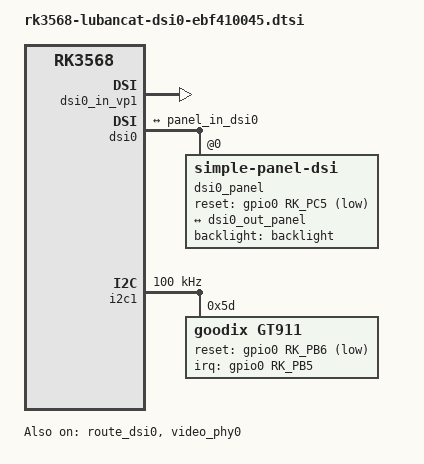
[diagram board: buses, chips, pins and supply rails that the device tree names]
// SPDX-License-Identifier: (GPL-2.0+ OR MIT)
/*
 * Copyright (c) 2020 Rockchip Electronics Co., Ltd.
 *
 */

&route_dsi0 {
	status = "okay";
	connect = <&vp1_out_dsi0>;
};

&video_phy0 {
	status = "okay";
};

&dsi0_in_vp0 {
	status = "disabled";
};

&dsi0_in_vp1 {
	status = "okay";
};

&dsi0 {
	status = "okay";

	dsi0_panel: panel@0 {
		status = "okay";
		compatible = "simple-panel-dsi";
		reg = <0>;
		backlight = <&backlight>;
		reset-gpios = <&gpio0 RK_PC5 GPIO_ACTIVE_LOW>;

		enable-delay-ms = <35>;
		prepare-delay-ms = <6>;
		reset-delay-ms = <0>;
		init-delay-ms = <20>;
		unprepare-delay-ms = <0>;
		disable-delay-ms = <20>;

		size,width = <68>;
		size,height = <121>;

		dsi,flags = <(MIPI_DSI_MODE_VIDEO | MIPI_DSI_MODE_VIDEO_BURST | MIPI_DSI_MODE_LPM | MIPI_DSI_MODE_EOT_PACKET)>;
		dsi,format = <MIPI_DSI_FMT_RGB888>;
		dsi,lanes  = <4>;

		panel-init-sequence = [
			15 00 04 FF 98 81 03
			15 00 02 01 00
			15 00 02 02 00
			15 00 02 03 72
			15 00 02 04 00
			15 00 02 05 00
			15 00 02 06 09
			15 00 02 07 00
			15 00 02 08 00
			15 00 02 09 01
			15 00 02 0A 00
			15 00 02 0B 00
			15 00 02 0C 01
			15 00 02 0D 00
			15 00 02 0E 00
			15 00 02 0F 00
			15 00 02 10 00
			15 00 02 11 00
			15 00 02 12 00
			15 00 02 13 00
			15 00 02 14 00
			15 00 02 15 00
			15 00 02 16 00
			15 00 02 17 00
			15 00 02 18 00
			15 00 02 19 00
			15 00 02 1A 00
			15 00 02 1B 00
			15 00 02 1C 00
			15 00 02 1D 00
			15 00 02 1E 40
			15 00 02 1F 80
			15 00 02 20 05
			15 00 02 21 02
			15 00 02 22 00
			15 00 02 23 00
			15 00 02 24 00
			15 00 02 25 00
			15 00 02 26 00
			15 00 02 27 00
			15 00 02 28 33
			15 00 02 29 02
			15 00 02 2A 00
			15 00 02 2B 00
			15 00 02 2C 00
			15 00 02 2D 00
			15 00 02 2E 00
			15 00 02 2F 00
			15 00 02 30 00
			15 00 02 31 00
			15 00 02 32 00
			15 00 02 33 00
			15 00 02 34 00
			15 00 02 35 00
			15 00 02 36 00
			15 00 02 37 00
			15 00 02 38 3C
			15 00 02 39 00
			15 00 02 3A 40
			15 00 02 3B 40
			15 00 02 3C 00
			15 00 02 3D 00
			15 00 02 3E 00
			15 00 02 3F 00
			15 00 02 40 00
			15 00 02 41 00
			15 00 02 42 00
			15 00 02 43 00
			15 00 02 44 00
			15 00 02 50 00
			15 00 02 51 23
			15 00 02 52 45
			15 00 02 53 67
			15 00 02 54 89
			15 00 02 55 AB
			15 00 02 56 01
			15 00 02 57 23
			15 00 02 58 45
			15 00 02 59 67
			15 00 02 5A 89
			15 00 02 5B AB
			15 00 02 5C CD
			15 00 02 5D EF
			15 00 02 5E 11
			15 00 02 5F 01
			15 00 02 60 00
			15 00 02 61 15
			15 00 02 62 14
			15 00 02 63 0E
			15 00 02 64 0F
			15 00 02 65 0C
			15 00 02 66 0D
			15 00 02 67 06
			15 00 02 68 02
			15 00 02 69 02
			15 00 02 6A 02
			15 00 02 6B 02
			15 00 02 6C 02
			15 00 02 6D 02
			15 00 02 6E 07
			15 00 02 6F 02
			15 00 02 70 02
			15 00 02 71 02
			15 00 02 72 02
			15 00 02 73 02
			15 00 02 74 02
			15 00 02 75 01
			15 00 02 76 00
			15 00 02 77 14
			15 00 02 78 15
			15 00 02 79 0E
			15 00 02 7A 0F
			15 00 02 7B 0C
			15 00 02 7C 0D
			15 00 02 7D 06
			15 00 02 7E 02
			15 00 02 7F 07
			15 00 02 80 02
			15 00 02 81 02
			15 00 02 82 02
			15 00 02 83 02
			15 00 02 84 07
			15 00 02 85 02
			15 00 02 86 02
			15 00 02 87 02
			15 00 02 88 02
			15 00 02 89 02
			15 00 02 8A 02

			15 00 04 FF 98 81 04
			15 00 02 6C 15
			15 00 02 6E 2A
			15 00 02 6F 33
			15 00 02 3A 94
			15 00 02 8D 1A
			15 00 02 87 BA
			15 00 02 26 76
			15 00 02 B2 D1
			15 00 02 B5 06

			15 00 04 FF 98 81 01
			15 00 02 22 0A
			15 00 02 31 00
			15 00 02 53 8A
			15 00 02 55 8A
			15 00 02 50 AE
			15 00 02 51 AE
			15 00 02 60 28
			15 00 02 61 00
			15 00 02 62 19
			15 00 02 63 10
			15 00 02 A0 0F
			15 00 02 A1 1B
			15 00 02 A2 28
			15 00 02 A3 12
			15 00 02 A4 15
			15 00 02 A5 28
			15 00 02 A6 1B
			15 00 02 A7 1E
			15 00 02 A8 79
			15 00 02 A9 1B
			15 00 02 AA 27
			15 00 02 AB 69
			15 00 02 AC 19
			15 00 02 AD 18
			15 00 02 AE 4C
			15 00 02 AF 21
			15 00 02 B0 28
			15 00 02 B1 52
			15 00 02 B2 65
			15 00 02 B3 3F
			15 00 02 C0 04
			15 00 02 C1 1B
			15 00 02 C0 27
			15 00 02 C3 13
			15 00 02 C4 15
			15 00 02 C5 28
			15 00 02 C6 1C
			15 00 02 C7 1E
			15 00 02 C8 79
			15 00 02 C9 1A
			15 00 02 CA 27
			15 00 02 CB 69
			15 00 02 CC 1A
			15 00 02 CD 18
			15 00 02 CE 4C
			15 00 02 CF 21
			15 00 02 D0 27
			15 00 02 D1 52
			15 00 02 D2 65
			15 00 02 D3 3F

			15 00 04 FF 98 81 00
			15 00 02 35 00
			15 00 02 3A 70
			15 78 01 11
			15 19 01 29
		];

		panel-exit-sequence = [
			05 78 01 11
			05 00 01 29
		];

		disp_timings0: display-timings {
			native-mode = <&dsi0_timing0>;
			dsi0_timing0: timing0 {
				clock-frequency = <59603040>;
				hactive = <720>;
				vactive = <1280>;
				hsync-len = <6>;
				hback-porch = <20>;
				hfront-porch = <10>;
				vsync-len = <4>;
				vback-porch = <20>;
				vfront-porch = <10>;
				hsync-active = <0>;
				vsync-active = <0>;
				de-active = <0>;
				pixelclk-active = <0>;
			};
		};

		ports {
			#address-cells = <1>;
			#size-cells = <0>;
			port@0 {
				reg = <0>;
				panel_in_dsi0: endpoint {
					remote-endpoint = <&dsi0_out_panel>;
				};
			};
		};
	};

	ports {
		#address-cells = <1>;
		#size-cells = <0>;

		port@1 {
			reg = <1>;
			dsi0_out_panel: endpoint {
				remote-endpoint = <&panel_in_dsi0>;
			};
		};
	};
};

&i2c1 {
	status = "okay";
	clock-frequency = <100000>;

	gt911: gt911@5d {
		status = "okay";
		compatible = "goodix,gt911";
		reg = <0x5d>;
		interrupt-parent = <&gpio0>;
		interrupts = <RK_PB5 IRQ_TYPE_LEVEL_LOW>;
		reset-gpios = <&gpio0 RK_PB6 GPIO_ACTIVE_LOW>;
		irq-gpios = <&gpio0 RK_PB5 GPIO_ACTIVE_HIGH>;
	};
};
